AUTOSAR XML (schema 00046)
package /Cluster
  can cluster CanA
    can physical channel Channel
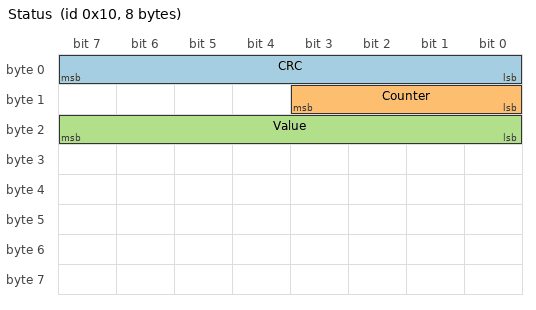
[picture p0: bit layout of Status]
      frame Status: id 0x10, frame-length=8, can-addressing-mode=STANDARD
        pdu Status: length=8
          signal CRC: start 0, 8 bit, little-endian
          signal Counter: start 8, 4 bit, little-endian
          signal Value: start 16, 8 bit, little-endian
          mapping StatusGroup: i-signal-group=StatusGroup
  can cluster CanB
    can physical channel Channel
      frame Other: id 0x20, frame-length=8, can-addressing-mode=STANDARD
        pdu Other: length=8
          signal Speed: start 0, 8 bit, little-endian
package /ISignal
  i signal group StatusGroup: i-signal=Value, end-to-end-transformation-i-signal-props{transformer=Profile2, data-ids=[1, 2, 3, 4, 5, 6, 7, 8, 9, 10, 11, 12, 13, 14, 15, 16]}
package /Transformers
  data transformation set E2E
    transformation technology Profile2: protocol=E2E, end-to-end-transformation-description=profile-name=Profile2
